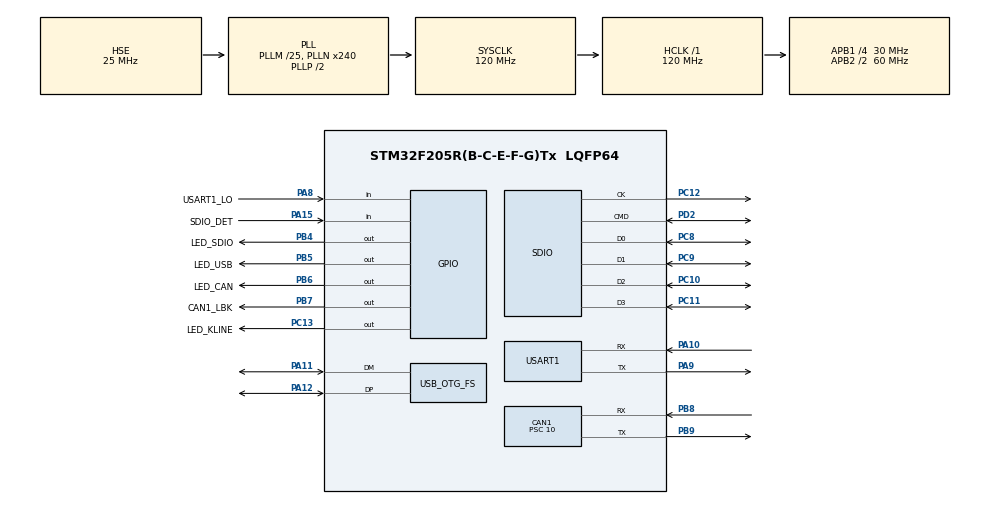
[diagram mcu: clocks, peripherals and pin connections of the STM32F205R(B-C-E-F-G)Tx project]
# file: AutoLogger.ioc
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CAN1.BS1=CAN_BS1_4TQ
CAN1.CalculateBaudRate=499999
CAN1.CalculateTimeBit=2000
CAN1.CalculateTimeQuantum=333.33333333333337
CAN1.Prescaler=10
CAN1.SJW=CAN_SJW_2TQ
Dma.Request0=SDIO_RX
Dma.Request1=SDIO_TX
Dma.Request2=USART1_RX
Dma.Request3=USART1_TX
Dma.SDIO_RX.0.Direction=DMA_PERIPH_TO_MEMORY
Dma.SDIO_RX.0.FIFOMode=DMA_FIFOMODE_ENABLE
Dma.SDIO_RX.0.FIFOThreshold=DMA_FIFO_THRESHOLD_FULL
Dma.SDIO_RX.0.Instance=DMA2_Stream3
Dma.SDIO_RX.0.MemBurst=DMA_MBURST_SINGLE
Dma.SDIO_RX.0.MemDataAlignment=DMA_MDATAALIGN_BYTE
Dma.SDIO_RX.0.MemInc=DMA_MINC_ENABLE
Dma.SDIO_RX.0.Mode=DMA_PFCTRL
Dma.SDIO_RX.0.PeriphBurst=DMA_PBURST_INC4
Dma.SDIO_RX.0.PeriphDataAlignment=DMA_PDATAALIGN_WORD
Dma.SDIO_RX.0.PeriphInc=DMA_PINC_DISABLE
Dma.SDIO_RX.0.Priority=DMA_PRIORITY_LOW
Dma.SDIO_TX.1.Direction=DMA_MEMORY_TO_PERIPH
Dma.SDIO_TX.1.FIFOMode=DMA_FIFOMODE_ENABLE
Dma.SDIO_TX.1.FIFOThreshold=DMA_FIFO_THRESHOLD_FULL
Dma.SDIO_TX.1.Instance=DMA2_Stream6
Dma.SDIO_TX.1.MemBurst=DMA_MBURST_SINGLE
Dma.SDIO_TX.1.MemDataAlignment=DMA_MDATAALIGN_BYTE
Dma.SDIO_TX.1.MemInc=DMA_MINC_ENABLE
Dma.SDIO_TX.1.Mode=DMA_PFCTRL
Dma.SDIO_TX.1.PeriphBurst=DMA_PBURST_INC4
Dma.SDIO_TX.1.PeriphDataAlignment=DMA_PDATAALIGN_WORD
Dma.SDIO_TX.1.PeriphInc=DMA_PINC_DISABLE
Dma.SDIO_TX.1.Priority=DMA_PRIORITY_LOW
Dma.USART1_RX.2.Direction=DMA_PERIPH_TO_MEMORY
Dma.USART1_RX.2.FIFOMode=DMA_FIFOMODE_DISABLE
Dma.USART1_RX.2.Instance=DMA2_Stream2
Dma.USART1_RX.2.MemDataAlignment=DMA_MDATAALIGN_BYTE
Dma.USART1_RX.2.MemInc=DMA_MINC_ENABLE
Dma.USART1_RX.2.Mode=DMA_CIRCULAR
Dma.USART1_RX.2.PeriphDataAlignment=DMA_PDATAALIGN_BYTE
Dma.USART1_RX.2.PeriphInc=DMA_PINC_DISABLE
Dma.USART1_RX.2.Priority=DMA_PRIORITY_LOW
Dma.USART1_TX.3.Direction=DMA_MEMORY_TO_PERIPH
Dma.USART1_TX.3.FIFOMode=DMA_FIFOMODE_DISABLE
Dma.USART1_TX.3.Instance=DMA2_Stream7
Dma.USART1_TX.3.MemDataAlignment=DMA_MDATAALIGN_BYTE
Dma.USART1_TX.3.MemInc=DMA_MINC_ENABLE
Dma.USART1_TX.3.Mode=DMA_NORMAL
Dma.USART1_TX.3.PeriphDataAlignment=DMA_PDATAALIGN_BYTE
Dma.USART1_TX.3.PeriphInc=DMA_PINC_DISABLE
Dma.USART1_TX.3.Priority=DMA_PRIORITY_LOW
FATFS.BSP.number=1
FATFS._USE_FIND=1
FATFS0.BSP.STBoard=false
FATFS0.BSP.api=Unknown
FATFS0.BSP.i2caddr=0
FATFS0.BSP.instance=PA15
FATFS0.BSP.ip=GPIO
FATFS0.BSP.mode=Input
FATFS0.BSP.name=Detect_SDIO
FATFS0.BSP.solution=PA15
FREERTOS.Tasks01=defaultTask,24,256,StartDefaultTask,Default,NULL,Dynamic,NULL,NULL
FREERTOS.configMINIMAL_STACK_SIZE=256
FREERTOS.configUSE_NEWLIB_REENTRANT=1
Mcu.Family=STM32F2
Mcu.Name=STM32F205R(B-C-E-F-G)Tx
Mcu.Package=LQFP64
NVIC.CAN1_RX0_IRQn=true\:5\:0\:false\:false\:true\:true\:true\:true\:true
NVIC.CAN1_RX1_IRQn=true\:5\:0\:false\:false\:true\:true\:true\:true\:true
NVIC.CAN1_SCE_IRQn=true\:5\:0\:false\:false\:true\:true\:true\:true\:true
NVIC.CAN1_TX_IRQn=true\:5\:0\:false\:false\:true\:true\:true\:true\:true
NVIC.DMA2_Stream2_IRQn=true\:5\:0\:false\:false\:true\:true\:false\:true\:true
NVIC.DMA2_Stream3_IRQn=true\:5\:0\:false\:false\:true\:true\:false\:true\:true
NVIC.DMA2_Stream6_IRQn=true\:5\:0\:false\:false\:true\:true\:false\:true\:true
NVIC.DMA2_Stream7_IRQn=true\:5\:0\:false\:false\:true\:true\:false\:true\:true
NVIC.OTG_FS_IRQn=true\:5\:0\:false\:false\:true\:true\:true\:true\:true
NVIC.PriorityGroup=NVIC_PRIORITYGROUP_4
NVIC.SDIO_IRQn=true\:5\:0\:false\:false\:true\:true\:true\:true\:true
NVIC.TIM7_IRQn=true\:5\:0\:false\:false\:true\:true\:true\:true\:true
NVIC.USART1_IRQn=true\:5\:0\:false\:false\:true\:true\:true\:true\:true
PA10.GPIO_PuPd=GPIO_PULLUP
PA10.Mode=Asynchronous
PA10.Signal=USART1_RX
PA11.GPIO_PuPd=GPIO_PULLUP
PA11.Mode=Host_Only
PA11.Signal=USB_OTG_FS_DM
PA12.GPIO_PuPd=GPIO_PULLUP
PA12.Mode=Host_Only
PA12.Signal=USB_OTG_FS_DP
PA13.Mode=Trace_Asynchronous_SW
PA13.Signal=SYS_JTMS-SWDIO
PA14.Mode=Trace_Asynchronous_SW
PA14.Signal=SYS_JTCK-SWCLK
PA15.GPIO_Label=SDIO_DET
PA15.GPIO_PuPd=GPIO_PULLUP
PA15.Signal=GPIO_Input
PA8.GPIO_Label=USART1_LO
PA8.GPIO_PuPd=GPIO_PULLUP
PA8.Signal=GPIO_Input
PA9.GPIO_PuPd=GPIO_PULLUP
PA9.Mode=Asynchronous
PA9.Signal=USART1_TX
PB3.Mode=Trace_Asynchronous_SW
PB3.Signal=SYS_JTDO-SWO
PB4.GPIO_Label=LED_SDIO
PB4.GPIO_ModeDefaultOutputPP=GPIO_MODE_OUTPUT_OD
PB4.GPIO_PuPd=GPIO_NOPULL
PB4.PinState=GPIO_PIN_SET
PB4.Signal=GPIO_Output
PB5.GPIO_Label=LED_USB
PB5.GPIO_ModeDefaultOutputPP=GPIO_MODE_OUTPUT_OD
PB5.GPIO_PuPd=GPIO_NOPULL
PB5.PinState=GPIO_PIN_SET
PB5.Signal=GPIO_Output
PB6.GPIO_Label=LED_CAN
PB6.GPIO_ModeDefaultOutputPP=GPIO_MODE_OUTPUT_OD
PB6.GPIO_PuPd=GPIO_NOPULL
PB6.PinState=GPIO_PIN_SET
PB6.Signal=GPIO_Output
PB7.GPIO_Label=CAN1_LBK
PB7.GPIO_Speed=GPIO_SPEED_FREQ_VERY_HIGH
PB7.PinState=GPIO_PIN_SET
PB7.Signal=GPIO_Output
PB8.GPIO_PuPd=GPIO_PULLUP
PB8.Mode=CAN_Activate
PB8.Signal=CAN1_RX
PB9.GPIO_PuPd=GPIO_PULLUP
PB9.Mode=CAN_Activate
PB9.Signal=CAN1_TX
PC10.GPIO_PuPd=GPIO_PULLUP
PC10.Mode=SD_4_bits_Wide_bus
PC10.Signal=SDIO_D2
PC11.GPIO_PuPd=GPIO_PULLUP
PC11.Mode=SD_4_bits_Wide_bus
PC11.Signal=SDIO_D3
PC12.GPIO_PuPd=GPIO_PULLUP
PC12.Mode=SD_4_bits_Wide_bus
PC12.Signal=SDIO_CK
PC13.GPIO_Label=LED_KLINE
PC13.GPIO_ModeDefaultOutputPP=GPIO_MODE_OUTPUT_OD
PC13.GPIO_PuPd=GPIO_NOPULL
PC13.PinState=GPIO_PIN_SET
PC13.Signal=GPIO_Output
PC8.GPIO_PuPd=GPIO_PULLUP
PC8.Mode=SD_4_bits_Wide_bus
PC8.Signal=SDIO_D0
PC9.GPIO_PuPd=GPIO_PULLUP
PC9.Mode=SD_4_bits_Wide_bus
PC9.Signal=SDIO_D1
PD2.GPIO_PuPd=GPIO_PULLUP
PD2.Mode=SD_4_bits_Wide_bus
PD2.Signal=SDIO_CMD
PH0-OSC_IN.Mode=HSE-External-Oscillator
PH0-OSC_IN.Signal=RCC_OSC_IN
PH1-OSC_OUT.Mode=HSE-External-Oscillator
PH1-OSC_OUT.Signal=RCC_OSC_OUT
ProjectManager.HeapSize=0x200
ProjectManager.StackSize=0x400
ProjectManager.TargetToolchain=STM32CubeIDE
RCC.48MHZClocksFreq_Value=48000000
RCC.AHBFreq_Value=120000000
RCC.APB1CLKDivider=RCC_HCLK_DIV4
RCC.APB1Freq_Value=30000000
RCC.APB1TimFreq_Value=60000000
RCC.APB2CLKDivider=RCC_HCLK_DIV2
RCC.APB2Freq_Value=60000000
RCC.APB2TimFreq_Value=120000000
RCC.CortexFreq_Value=120000000
RCC.HCLKFreq_Value=120000000
RCC.HSE_VALUE=25000000
RCC.HSI_VALUE=16000000
RCC.LSE_VALUE=32768
RCC.PLLM=25
RCC.PLLN=240
RCC.PLLQ=5
RCC.PLLSourceVirtual=RCC_PLLSOURCE_HSE
RCC.RCC_RTC_Clock_SourceVirtual=RCC_RTCCLKSOURCE_HSE_DIV25
RCC.RCC_RTC_Clock_Source_FROM_HSE=RCC_RTCCLKSOURCE_HSE_DIV25
RCC.SYSCLKFreq_VALUE=120000000
RCC.SYSCLKSource=RCC_SYSCLKSOURCE_PLLCLK
RCC.VCOOutputFreq_Value=240000000
RTC.AsynchPrediv=49
RTC.SynchPrediv=19999
TIM7.Period=1000-1
TIM7.Prescaler=60-1
USART1.VirtualMode=VM_ASYNC
USB_HOST.USBH_HandleTypeDef-MSC_FS=hUsbHostFS
USB_HOST.VirtualModeFS=Msc
USB_OTG_FS.VirtualMode=Host_Only
USB_OTG_FS.phy_itface=HCD_PHY_EMBEDDED
VP_FATFS_VS_SDIO.Mode=SDIO
VP_FATFS_VS_USB.Mode=USB
VP_FREERTOS_VS_CMSIS_V2.Mode=CMSIS_V2
VP_IWDG_VS_IWDG.Mode=IWDG_Activate
VP_RTC_VS_RTC_Activate.Mode=RTC_Enabled
VP_TIM7_VS_ClockSourceINT.Mode=Enable_Timer
VP_USB_HOST_VS_USB_HOST_MSC_FS.Mode=MSC_FS
board=custom

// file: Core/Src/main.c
#include "main.h"
#include "cmsis_os.h"
#include "fatfs.h"
#include "led.h"
#include "can.h"

CAN_HandleTypeDef hcan1;

IWDG_HandleTypeDef hiwdg;

RTC_HandleTypeDef hrtc;
RTC_TimeTypeDef sTime;
RTC_DateTypeDef sDate;

SD_HandleTypeDef hsd;
DMA_HandleTypeDef hdma_sdio_rx;
DMA_HandleTypeDef hdma_sdio_tx;

TIM_HandleTypeDef htim7;

UART_HandleTypeDef huart1;
DMA_HandleTypeDef hdma_usart1_rx;
DMA_HandleTypeDef hdma_usart1_tx;

void SystemClock_Config(void);
static void MX_GPIO_Init(void);
static void MX_DMA_Init(void);
static void MX_SDIO_SD_Init(void);
static void MX_USART1_UART_Init(void);
static void MX_CAN1_Init(void);
static void MX_IWDG_Init(void);
static void MX_RTC_Init(void);
static void MX_TIM7_Init(void);
extern void tasksInit(void);

void HAL_CAN_TxMailbox0AbortCallback(CAN_HandleTypeDef *hcan)
{
  if(hcan == &hcan1) {
    can_txfifo_aborted_callback(hcan, CAN_TX_MAILBOX0);
  }
}

void HAL_CAN_TxMailbox1AbortCallback(CAN_HandleTypeDef *hcan)
{
  if(hcan == &hcan1) {
    can_txfifo_aborted_callback(hcan, CAN_TX_MAILBOX1);
  }
}

void HAL_CAN_TxMailbox2AbortCallback(CAN_HandleTypeDef *hcan)
{
  if(hcan == &hcan1) {
    can_txfifo_aborted_callback(hcan, CAN_TX_MAILBOX2);
  }
}

void HAL_CAN_TxMailbox0CompleteCallback(CAN_HandleTypeDef *hcan)
{
  if(hcan == &hcan1) {
    can_txfifo_completed_callback(hcan, CAN_TX_MAILBOX0);
  }
}

void HAL_CAN_TxMailbox1CompleteCallback(CAN_HandleTypeDef *hcan)
{
  if(hcan == &hcan1) {
    can_txfifo_completed_callback(hcan, CAN_TX_MAILBOX1);
  }
}

void HAL_CAN_TxMailbox2CompleteCallback(CAN_HandleTypeDef *hcan)
{
  if(hcan == &hcan1) {
    can_txfifo_completed_callback(hcan, CAN_TX_MAILBOX2);
  }
}

void HAL_CAN_RxFifo0MsgPendingCallback(CAN_HandleTypeDef *hcan)
{
  if(hcan == &hcan1) {
    can_rxfifo_pending_callback(hcan, CAN_RX_FIFO0);
  }
}

void HAL_CAN_RxFifo1MsgPendingCallback(CAN_HandleTypeDef *hcan)
{
  if(hcan == &hcan1) {
    can_rxfifo_pending_callback(hcan, CAN_RX_FIFO1);
  }
}

int main(void)
{
  HAL_Init();

  SystemClock_Config();

  MX_GPIO_Init();
  MX_DMA_Init();
  //MX_IWDG_Init();
  MX_SDIO_SD_Init();
  MX_USART1_UART_Init();
  MX_FATFS_Init();
  MX_CAN1_Init();
  MX_RTC_Init();
  MX_TIM7_Init();

  osKernelInitialize();

  tasksInit();

  led_init();
  led_register(LedUsb, LED_USB_GPIO_Port, LED_USB_Pin, LedOff);
  led_register(LedSdio, LED_SDIO_GPIO_Port, LED_SDIO_Pin, LedOff);
  led_register(LedCan, LED_CAN_GPIO_Port, LED_CAN_Pin, LedOff);
  led_register(LedKline, LED_KLINE_GPIO_Port, LED_KLINE_Pin, LedOff);

  HAL_TIM_Base_Start_IT(&htim7);

  osKernelStart();

  while (1)
  {
  }
}

void SystemClock_Config(void)
{
  RCC_OscInitTypeDef RCC_OscInitStruct = {0};
  RCC_ClkInitTypeDef RCC_ClkInitStruct = {0};
  RCC_PeriphCLKInitTypeDef PeriphClkInitStruct = {0};

  /** Initializes the RCC Oscillators according to the specified parameters
  * in the RCC_OscInitTypeDef structure.
  */
  RCC_OscInitStruct.OscillatorType = RCC_OSCILLATORTYPE_LSI|RCC_OSCILLATORTYPE_HSE;
  RCC_OscInitStruct.HSEState = RCC_HSE_ON;
  RCC_OscInitStruct.LSIState = RCC_LSI_ON;
  RCC_OscInitStruct.PLL.PLLState = RCC_PLL_ON;
  RCC_OscInitStruct.PLL.PLLSource = RCC_PLLSOURCE_HSE;
  RCC_OscInitStruct.PLL.PLLM = 25;
  RCC_OscInitStruct.PLL.PLLN = 240;
  RCC_OscInitStruct.PLL.PLLP = RCC_PLLP_DIV2;
  RCC_OscInitStruct.PLL.PLLQ = 5;
  if (HAL_RCC_OscConfig(&RCC_OscInitStruct) != HAL_OK)
  {
    Error_Handler();
  }

  /** Initializes the CPU, AHB and APB buses clocks
  */
  RCC_ClkInitStruct.ClockType = RCC_CLOCKTYPE_HCLK|RCC_CLOCKTYPE_SYSCLK
                              |RCC_CLOCKTYPE_PCLK1|RCC_CLOCKTYPE_PCLK2;
  RCC_ClkInitStruct.SYSCLKSource = RCC_SYSCLKSOURCE_PLLCLK;
  RCC_ClkInitStruct.AHBCLKDivider = RCC_SYSCLK_DIV1;
  RCC_ClkInitStruct.APB1CLKDivider = RCC_HCLK_DIV4;
  RCC_ClkInitStruct.APB2CLKDivider = RCC_HCLK_DIV2;

  if (HAL_RCC_ClockConfig(&RCC_ClkInitStruct, FLASH_LATENCY_3) != HAL_OK)
  {
    Error_Handler();
  }
  PeriphClkInitStruct.PeriphClockSelection = RCC_PERIPHCLK_RTC;
  PeriphClkInitStruct.RTCClockSelection = RCC_RTCCLKSOURCE_HSE_DIV25;
  if (HAL_RCCEx_PeriphCLKConfig(&PeriphClkInitStruct) != HAL_OK)
  {
    Error_Handler();
  }
}

static void MX_CAN1_Init(void)
{

  hcan1.Instance = CAN1;
  hcan1.Init.Prescaler = 10;
  hcan1.Init.Mode = CAN_MODE_NORMAL;
  hcan1.Init.SyncJumpWidth = CAN_SJW_2TQ;
  hcan1.Init.TimeSeg1 = CAN_BS1_3TQ;
  hcan1.Init.TimeSeg2 = CAN_BS2_2TQ;
  hcan1.Init.TimeTriggeredMode = DISABLE;
  hcan1.Init.AutoBusOff = DISABLE;
  hcan1.Init.AutoWakeUp = DISABLE;
  hcan1.Init.AutoRetransmission = ENABLE;
  hcan1.Init.ReceiveFifoLocked = DISABLE;
  hcan1.Init.TransmitFifoPriority = DISABLE;
  if (HAL_CAN_Init(&hcan1) != HAL_OK)
  {
    Error_Handler();
  }

}

static void MX_IWDG_Init(void)
{

  hiwdg.Instance = IWDG;
  hiwdg.Init.Prescaler = IWDG_PRESCALER_4;
  hiwdg.Init.Reload = 4095;
  if (HAL_IWDG_Init(&hiwdg) != HAL_OK)
  {
    Error_Handler();
  }

}

static void MX_RTC_Init(void)
{

  /** Initialize RTC Only
  */
  hrtc.Instance = RTC;
  hrtc.Init.HourFormat = RTC_HOURFORMAT_24;
  hrtc.Init.AsynchPrediv = 49;
  hrtc.Init.SynchPrediv = 19999;
  hrtc.Init.OutPut = RTC_OUTPUT_DISABLE;
  hrtc.Init.OutPutPolarity = RTC_OUTPUT_POLARITY_HIGH;
  hrtc.Init.OutPutType = RTC_OUTPUT_TYPE_OPENDRAIN;
  if (HAL_RTC_Init(&hrtc) != HAL_OK)
  {
    Error_Handler();
  }
  /* USER CODE BEGIN RTC_Init 2 */

  sDate.Date = 1;
  sDate.Month = 1;
  sDate.Year = 24;

  sTime.Hours = 9;
  sTime.Minutes = 0;
  sTime.Seconds = 0;

  if (HAL_RTC_SetTime(&hrtc, &sTime, FORMAT_BIN) != HAL_OK)
  {
    Error_Handler();
  }
  if (HAL_RTC_SetDate(&hrtc, &sDate, FORMAT_BIN) != HAL_OK)
  {
    Error_Handler();
  }

  /* USER CODE END RTC_Init 2 */

}

static void MX_SDIO_SD_Init(void)
{

  hsd.Instance = SDIO;
  hsd.Init.ClockEdge = SDIO_CLOCK_EDGE_RISING;
  hsd.Init.ClockBypass = SDIO_CLOCK_BYPASS_DISABLE;
  hsd.Init.ClockPowerSave = SDIO_CLOCK_POWER_SAVE_DISABLE;
  hsd.Init.BusWide = SDIO_BUS_WIDE_1B;
  hsd.Init.HardwareFlowControl = SDIO_HARDWARE_FLOW_CONTROL_DISABLE;
  hsd.Init.ClockDiv = 0;

}

static void MX_TIM7_Init(void)
{

  TIM_MasterConfigTypeDef sMasterConfig = {0};

  htim7.Instance = TIM7;
  htim7.Init.Prescaler = 60-1;
  htim7.Init.CounterMode = TIM_COUNTERMODE_UP;
  htim7.Init.Period = 1000-1;
  htim7.Init.AutoReloadPreload = TIM_AUTORELOAD_PRELOAD_DISABLE;
  if (HAL_TIM_Base_Init(&htim7) != HAL_OK)
  {
    Error_Handler();
  }
  sMasterConfig.MasterOutputTrigger = TIM_TRGO_RESET;
  sMasterConfig.MasterSlaveMode = TIM_MASTERSLAVEMODE_DISABLE;
  if (HAL_TIMEx_MasterConfigSynchronization(&htim7, &sMasterConfig) != HAL_OK)
  {
    Error_Handler();
  }

}

static void MX_USART1_UART_Init(void)
{

  huart1.Instance = USART1;
  huart1.Init.BaudRate = 10400;
  huart1.Init.WordLength = UART_WORDLENGTH_8B;
  huart1.Init.StopBits = UART_STOPBITS_1;
  huart1.Init.Parity = UART_PARITY_NONE;
  huart1.Init.Mode = UART_MODE_TX_RX;
  huart1.Init.HwFlowCtl = UART_HWCONTROL_NONE;
  huart1.Init.OverSampling = UART_OVERSAMPLING_16;
  if (HAL_UART_Init(&huart1) != HAL_OK)
  {
    Error_Handler();
  }

}

static void MX_DMA_Init(void)
{

  /* DMA controller clock enable */
  __HAL_RCC_DMA2_CLK_ENABLE();

  /* DMA interrupt init */
  /* DMA2_Stream2_IRQn interrupt configuration */
  HAL_NVIC_SetPriority(DMA2_Stream2_IRQn, 12, 0);
  HAL_NVIC_EnableIRQ(DMA2_Stream2_IRQn);
  /* DMA2_Stream3_IRQn interrupt configuration */
  HAL_NVIC_SetPriority(DMA2_Stream3_IRQn, 11, 0);
  HAL_NVIC_EnableIRQ(DMA2_Stream3_IRQn);
  /* DMA2_Stream6_IRQn interrupt configuration */
  HAL_NVIC_SetPriority(DMA2_Stream6_IRQn, 11, 0);
  HAL_NVIC_EnableIRQ(DMA2_Stream6_IRQn);
  /* DMA2_Stream7_IRQn interrupt configuration */
  HAL_NVIC_SetPriority(DMA2_Stream7_IRQn, 12, 0);
  HAL_NVIC_EnableIRQ(DMA2_Stream7_IRQn);

}

static void MX_GPIO_Init(void)
{
  GPIO_InitTypeDef GPIO_InitStruct = {0};

  /* GPIO Ports Clock Enable */
  __HAL_RCC_GPIOC_CLK_ENABLE();
  __HAL_RCC_GPIOH_CLK_ENABLE();
  __HAL_RCC_GPIOA_CLK_ENABLE();
  __HAL_RCC_GPIOD_CLK_ENABLE();
  __HAL_RCC_GPIOB_CLK_ENABLE();

  /*Configure GPIO pin Output Level */
  HAL_GPIO_WritePin(LED_KLINE_GPIO_Port, LED_KLINE_Pin, GPIO_PIN_SET);

  /*Configure GPIO pin Output Level */
  HAL_GPIO_WritePin(GPIOB, LED_SDIO_Pin|LED_USB_Pin|LED_CAN_Pin|CAN1_LBK_Pin, GPIO_PIN_SET);

  /*Configure GPIO pin : LED_KLINE_Pin */
  GPIO_InitStruct.Pin = LED_KLINE_Pin;
  GPIO_InitStruct.Mode = GPIO_MODE_OUTPUT_OD;
  GPIO_InitStruct.Pull = GPIO_NOPULL;
  GPIO_InitStruct.Speed = GPIO_SPEED_FREQ_LOW;
  HAL_GPIO_Init(LED_KLINE_GPIO_Port, &GPIO_InitStruct);

  /*Configure GPIO pins : USART1_LO_Pin SDIO_DET_Pin */
  GPIO_InitStruct.Pin = USART1_LO_Pin|SDIO_DET_Pin;
  GPIO_InitStruct.Mode = GPIO_MODE_INPUT;
  GPIO_InitStruct.Pull = GPIO_PULLUP;
  HAL_GPIO_Init(GPIOA, &GPIO_InitStruct);

  /*Configure GPIO pins : LED_SDIO_Pin LED_USB_Pin LED_CAN_Pin */
  GPIO_InitStruct.Pin = LED_SDIO_Pin|LED_USB_Pin|LED_CAN_Pin;
  GPIO_InitStruct.Mode = GPIO_MODE_OUTPUT_OD;
  GPIO_InitStruct.Pull = GPIO_NOPULL;
  GPIO_InitStruct.Speed = GPIO_SPEED_FREQ_LOW;
  HAL_GPIO_Init(GPIOB, &GPIO_InitStruct);

  /*Configure GPIO pin : CAN1_LBK_Pin */
  GPIO_InitStruct.Pin = CAN1_LBK_Pin;
  GPIO_InitStruct.Mode = GPIO_MODE_ANALOG;
  GPIO_InitStruct.Pull = GPIO_NOPULL;
  GPIO_InitStruct.Speed = GPIO_SPEED_FREQ_VERY_HIGH;
  HAL_GPIO_Init(CAN1_LBK_GPIO_Port, &GPIO_InitStruct);

}

void Error_Handler(void)
{
  __disable_irq();
  while (1)
  {
  }
}

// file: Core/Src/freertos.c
/* USER CODE BEGIN Header */
/**
  ******************************************************************************
  * File Name          : freertos.c
  * Description        : Code for freertos applications
  ******************************************************************************
  * @attention
  *
  * Copyright (c) 2022 STMicroelectronics.
  * All rights reserved.
  *
  * This software is licensed under terms that can be found in the LICENSE file
  * in the root directory of this software component.
  * If no LICENSE file comes with this software, it is provided AS-IS.
  *
  ******************************************************************************
  */
/* USER CODE END Header */

#include "cmsis_os.h"
#include "main.h"
#include "usb_host.h"
#include "fatfs.h"
#include "xProFIFO.h"
#include "led.h"
#include "structs.h"
#include "can.h"
#include "can_signals.h"
#include "can_signals_db.h"
#include <stdio.h>
#include <string.h>

#define CAN_LOOPBACK() HAL_GPIO_WritePin(CAN1_LBK_GPIO_Port, CAN1_LBK_Pin, GPIO_PIN_SET)
#define CAN_NORMAL() HAL_GPIO_WritePin(CAN1_LBK_GPIO_Port, CAN1_LBK_Pin, GPIO_PIN_RESET)

extern CAN_HandleTypeDef hcan1;
extern UART_HandleTypeDef huart1;
extern IWDG_HandleTypeDef hiwdg;

extern RTC_HandleTypeDef hrtc;
extern RTC_TimeTypeDef sTime;
extern RTC_DateTypeDef sDate;

/* Definitions for defaultTask */
osThreadId_t h_task_time;
osThreadId_t h_task_usb;
osThreadId_t h_task_sdio;
osThreadId_t h_task_can;
osThreadId_t h_task_kline;

volatile uint64_t gTick64 = 0;

char *uint64_to_str(uint64_t n, char dest[static 21]) {
    dest += 20;
    *dest-- = 0;
    while (n) {
        *dest-- = (n % 10) + '0';
        n /= 10;
    }
    return dest + 1;
}

#define LOG10_FROM_2_TO_64_PLUS_1  21
#define UINT64_TO_STR(n)  uint64_to_str(n, (char[21]){0})

typedef struct {
    const char *name;
    uint8_t type;
    uint32_t offset;
}sParameter;

/*
 * 0 = uint64_t
 * 1 = char *
 * 2 = int32_t
 * 3 = float
 * 4 = uint8_t
 * 5 = uint16_t
 */

const sParameter gParameters[] = {
    {"AdcKnockVoltage",           3, OFFSETOF(sParameters, AdcKnockVoltage)},
    {"AdcAirTemp",                3, OFFSETOF(sParameters, AdcAirTemp)},
    {"AdcEngineTemp",             3, OFFSETOF(sParameters, AdcEngineTemp)},
    {"AdcManifoldAirPressure",    3, OFFSETOF(sParameters, AdcManifoldAirPressure)},
    {"AdcThrottlePosition",       3, OFFSETOF(sParameters, AdcThrottlePosition)},
    {"AdcReferenceVoltage",       3, OFFSETOF(sParameters, AdcReferenceVoltage)},
    {"AdcLambdaUR",               3, OFFSETOF(sParameters, AdcLambdaUR)},
    {"AdcLambdaUA",               3, OFFSETOF(sParameters, AdcLambdaUA)},
    {"AdcEtcTps1",                3, OFFSETOF(sParameters, AdcEtcTps1)},
    {"AdcEtcTps2",                3, OFFSETOF(sParameters, AdcEtcTps2)},
    {"AdcEtcPedal1",              3, OFFSETOF(sParameters, AdcEtcPedal1)},
    {"AdcEtcPedal2",              3, OFFSETOF(sParameters, AdcEtcPedal2)},
    {"AdcEtcRsvd5",               3, OFFSETOF(sParameters, AdcEtcRsvd5)},
    {"AdcEtcRsvd6",               3, OFFSETOF(sParameters, AdcEtcRsvd6)},
    {"AdcEtcReferenceVoltage",    3, OFFSETOF(sParameters, AdcEtcReferenceVoltage)},
    {"AdcEtcPowerVoltage",        3, OFFSETOF(sParameters, AdcEtcPowerVoltage)},
    {"ThrottlePosition",          3, OFFSETOF(sParameters, ThrottlePosition)},
    {"PedalPosition",             3, OFFSETOF(sParameters, PedalPosition)},
    {"ThrottleDefaultPosition",   3, OFFSETOF(sParameters, ThrottleDefaultPosition)},
    {"ThrottleTargetPosition",    3, OFFSETOF(sParameters, ThrottleTargetPosition)},
    {"WishThrottleTargetPosition",3, OFFSETOF(sParameters, WishThrottleTargetPosition)},
    {"KnockSensor",               3, OFFSETOF(sParameters, KnockSensor)},
    {"KnockSensorFiltered",       3, OFFSETOF(sParameters, KnockSensorFiltered)},
    {"KnockSensorDetonate",       3, OFFSETOF(sParameters, KnockSensorDetonate)},
    {"KnockZone",                 3, OFFSETOF(sParameters, KnockZone)},
    {"KnockAdvance",              3, OFFSETOF(sParameters, KnockAdvance)},
    {"KnockSaturation",           3, OFFSETOF(sParameters, KnockSaturation)},
    {"AirTemp",                   3, OFFSETOF(sParameters, AirTemp)},
    {"EngineTemp",                3, OFFSETOF(sParameters, EngineTemp)},
    {"CalculatedAirTemp",         3, OFFSETOF(sParameters, CalculatedAirTemp)},
    {"ManifoldAirPressure",       3, OFFSETOF(sParameters, ManifoldAirPressure)},
    {"ReferenceVoltage",          3, OFFSETOF(sParameters, ReferenceVoltage)},
    {"PowerVoltage",              3, OFFSETOF(sParameters, PowerVoltage)},
    {"FuelRatio",                 3, OFFSETOF(sParameters, FuelRatio)},
    {"FuelRatioDiff",             3, OFFSETOF(sParameters, FuelRatioDiff)},
    {"LambdaValue",               3, OFFSETOF(sParameters, LambdaValue)},
    {"LambdaTemperature",         3, OFFSETOF(sParameters, LambdaTemperature)},
    {"LambdaHeaterVoltage",       3, OFFSETOF(sParameters, LambdaHeaterVoltage)},
    {"ShortTermCorrection",       3, OFFSETOF(sParameters, ShortTermCorrection)},
    {"LongTermCorrection",        3, OFFSETOF(sParameters, LongTermCorrection)},
    {"IdleCorrection",            3, OFFSETOF(sParameters, IdleCorrection)},
    {"RPM",                       3, OFFSETOF(sParameters, RPM)},
    {"Speed",                     3, OFFSETOF(sParameters, Speed)},
    {"MassAirFlow",               3, OFFSETOF(sParameters, MassAirFlow)},
    {"CyclicAirFlow",             3, OFFSETOF(sParameters, CyclicAirFlow)},
    {"EffectiveVolume",           3, OFFSETOF(sParameters, EffectiveVolume)},
    {"EngineLoad",                3, OFFSETOF(sParameters, EngineLoad)},
    {"EstimatedPower",            3, OFFSETOF(sParameters, EstimatedPower)},
    {"EstimatedTorque",           3, OFFSETOF(sParameters, EstimatedTorque)},
    {"WishFuelRatio",             3, OFFSETOF(sParameters, WishFuelRatio)},
    {"IdleValvePosition",         3, OFFSETOF(sParameters, IdleValvePosition)},
    {"IdleRegThrRPM",             3, OFFSETOF(sParameters, IdleRegThrRPM)},
    {"WishIdleRPM",               3, OFFSETOF(sParameters, WishIdleRPM)},
    {"WishIdleMassAirFlow",       3, OFFSETOF(sParameters, WishIdleMassAirFlow)},
    {"WishIdleValvePosition",     3, OFFSETOF(sParameters, WishIdleValvePosition)},
    {"WishIdleIgnitionAdvance",   3, OFFSETOF(sParameters, WishIdleIgnitionAdvance)},
    {"IgnitionAdvance",           3, OFFSETOF(sParameters, IgnitionAdvance)},
    {"InjectionPhase",            3, OFFSETOF(sParameters, InjectionPhase)},
    {"InjectionPhaseDuration",    3, OFFSETOF(sParameters, InjectionPhaseDuration)},
    {"InjectionPulse",            3, OFFSETOF(sParameters, InjectionPulse)},
    {"InjectionDutyCycle",        3, OFFSETOF(sParameters, InjectionDutyCycle)},
    {"InjectionEnrichment",       3, OFFSETOF(sParameters, InjectionEnrichment)},
    {"InjectionLag",              3, OFFSETOF(sParameters, InjectionLag)},
    {"IgnitionPulse",             3, OFFSETOF(sParameters, IgnitionPulse)},
    {"IdleSpeedShift",            3, OFFSETOF(sParameters, IdleSpeedShift)},
    {"EnrichmentSyncAmount",      3, OFFSETOF(sParameters, EnrichmentSyncAmount)},
    {"EnrichmentAsyncAmount",     3, OFFSETOF(sParameters, EnrichmentAsyncAmount)},
    {"EnrichmentStartLoad",       3, OFFSETOF(sParameters, EnrichmentStartLoad)},
    {"EnrichmentLoadDerivative",  3, OFFSETOF(sParameters, EnrichmentLoadDerivative)},
    {"DrivenKilometers",          3, OFFSETOF(sParameters, DrivenKilometers)},
    {"FuelConsumed",              3, OFFSETOF(sParameters, FuelConsumed)},
    {"FuelConsumption",           3, OFFSETOF(sParameters, FuelConsumption)},
    {"FuelHourly",                3, OFFSETOF(sParameters, FuelHourly)},
    {"TspsRelativePosition",      3, OFFSETOF(sParameters, TspsRelativePosition)},
    {"IdleWishToRpmRelation",     3, OFFSETOF(sParameters, IdleWishToRpmRelation)},
    {"KnockCount",                5, OFFSETOF(sParameters, KnockCount)},
    {"KnockCountCy1",             5, OFFSETOF(sParameters, KnockCountCy[0])},
    {"KnockCountCy2",             5, OFFSETOF(sParameters, KnockCountCy[1])},
    {"KnockCountCy3",             5, OFFSETOF(sParameters, KnockCountCy[2])},
    {"KnockCountCy4",             5, OFFSETOF(sParameters, KnockCountCy[3])},
    {"SwitchPosition",            4, OFFSETOF(sParameters, SwitchPosition)},
    {"CurrentTable",              4, OFFSETOF(sParameters, CurrentTable)},
    {"InjectorChannel",           4, OFFSETOF(sParameters, InjectorChannel)},
    {"IdleFlag",                  4, OFFSETOF(sParameters, IdleFlag)},
    {"IdleCorrFlag",              4, OFFSETOF(sParameters, IdleCorrFlag)},
    {"IdleEconFlag",              4, OFFSETOF(sParameters, IdleEconFlag)},
    {"LambdaValid",               4, OFFSETOF(sParameters, LambdaValid)},
    {"OilSensor",                 4, OFFSETOF(sParameters, OilSensor)},
    {"FanForceSwitch",            4, OFFSETOF(sParameters, FanForceSwitch)},
    {"HandbrakeSensor",           4, OFFSETOF(sParameters, HandbrakeSensor)},
    {"ChargeSensor",              4, OFFSETOF(sParameters, ChargeSensor)},
    {"ClutchSensor",              4, OFFSETOF(sParameters, ClutchSensor)},
    {"IgnSensor",                 4, OFFSETOF(sParameters, IgnSensor)},
    {"FuelPumpRelay",             4, OFFSETOF(sParameters, FuelPumpRelay)},
    {"FanRelay",                  4, OFFSETOF(sParameters, FanRelay)},
    {"CheckEngine",               4, OFFSETOF(sParameters, CheckEngine)},
    {"StarterRelay",              4, OFFSETOF(sParameters, StarterRelay)},
    {"FanSwitch",                 4, OFFSETOF(sParameters, FanSwitch)},
    {"IgnOutput",                 4, OFFSETOF(sParameters, IgnOutput)},
    {"StartAllowed",              4, OFFSETOF(sParameters, StartAllowed)},
    {"IsRunning",                 4, OFFSETOF(sParameters, IsRunning)},
    {"IsCheckEngine",             4, OFFSETOF(sParameters, IsCheckEngine)},

    {"EtcMotorActiveFlag",        4, OFFSETOF(sParameters, EtcMotorActiveFlag)},
    {"EtcStandaloneFlag",         4, OFFSETOF(sParameters, EtcStandaloneFlag)},
    {"EtcMotorFullCloseFlag",     4, OFFSETOF(sParameters, EtcMotorFullCloseFlag)},

    {"EtcOutCruizeG",             4, OFFSETOF(sParameters, EtcOutCruizeG)},
    {"EtcOutCruizeR",             4, OFFSETOF(sParameters, EtcOutCruizeR)},
    {"EtcOutRsvd3",               4, OFFSETOF(sParameters, EtcOutRsvd3)},
    {"EtcOutRsvd4",               4, OFFSETOF(sParameters, EtcOutRsvd4)},
    {"EtcInCruizeStart",          4, OFFSETOF(sParameters, EtcInCruizeStart)},
    {"EtcInCruizeStop",           4, OFFSETOF(sParameters, EtcInCruizeStop)},
    {"EtcInBrake",                4, OFFSETOF(sParameters, EtcInBrake)},
    {"EtcInRsvd4",                4, OFFSETOF(sParameters, EtcInRsvd4)},
    {"EtcInRsvd5",                4, OFFSETOF(sParameters, EtcInRsvd5)},
    {"EtcInRsvd6",                4, OFFSETOF(sParameters, EtcInRsvd6)},

    {"CylinderIgnitionBitmask",   4, OFFSETOF(sParameters, CylinderIgnitionBitmask)},
    {"CylinderInjectionBitmask",  4, OFFSETOF(sParameters, CylinderInjectionBitmask)}

};

#define BIT_GET(array,bit) ((array)[(bit) >> 3] & (1 << ((bit) & 7)))
#define BIT_SET(array,bit)   ((array)[(bit) >> 3] |= (1 << ((bit) & 7)))
#define BIT_RESET(array,bit)   ((array)[(bit) >> 3] &= ~(1 << ((bit) & 7)))
static uint8_t gConfigBitmap[16] = {0};

const char *gFileInitialHeader = "TimePoint";

typedef struct {
    uint64_t timestamp;
    sParameters params;
}sLoggerParameters;

#define PARAMS_BUFFER_SIZE 40
static sLoggerParameters gParamsBuffer[2][PARAMS_BUFFER_SIZE];
static sProFIFO gParamsFifo[2];

const osThreadAttr_t attrs_task_time = {
  .name = "taskTime",
  .stack_size = 256 * 4,
  .priority = (osPriority_t) osPriorityHigh,
};

const osThreadAttr_t attrs_task_usb = {
  .name = "taskUsb",
  .stack_size = 2048 * 4,
  .priority = (osPriority_t) osPriorityNormal,
};

const osThreadAttr_t attrs_task_sdio = {
  .name = "taskSdio",
  .stack_size = 2048 * 4,
  .priority = (osPriority_t) osPriorityNormal,
};

const osThreadAttr_t attrs_task_can = {
  .name = "taskCan",
  .stack_size = 2048 * 4,
  .priority = (osPriority_t) osPriorityAboveNormal,
};

const osThreadAttr_t attrs_task_kline = {
  .name = "taskKline",
  .stack_size = 2048 * 4,
  .priority = (osPriority_t) osPriorityAboveNormal,
};

void StartTimeTask(void *argument)
{
  for(;;)
  {
    HAL_RTC_GetTime(&hrtc, &sTime, FORMAT_BIN);
    HAL_RTC_GetDate(&hrtc, &sDate, FORMAT_BIN);
    osDelay(100);
  }
}

void HAL_TIM_PeriodElapsedCallback(TIM_HandleTypeDef *htim)
{
  if(htim->Instance == TIM7) {
    led_irq();
    gTick64++;
  }
}

struct sLogDriver {
    uint8_t initialized;
    uint8_t was_initialized;
    FRESULT fres;
    char filename[32];
    char string[128];
    uint16_t filenumber;
    UINT read;
    UINT wrote;
    sLoggerParameters parameters;
    uint64_t InitTime64;
    uint64_t diff;
    uint64_t sync_last;

    eLed led;
    FATFS *fatfs;
    FIL *file;
    const char *path;
    sProFIFO *fifo;
};

static void driver_loop(struct sLogDriver *driver)
{
  uint32_t readpos;

  led_set(driver->led, LedOff);
  led_set_post(driver->led, LedOff);

  for(;;)
  {
    if(!driver->initialized) {
      if(!driver->initialized && driver->was_initialized) {
        f_close(driver->file);
        f_mount(NULL, driver->path, 0);
        driver->was_initialized = 0;
      }

      osDelay(10);

      driver->fres = f_mount(driver->fatfs, driver->path, 1);
      if(driver->fres != FR_OK) {
        led_set(driver->led, LedOff);
        led_set_post(driver->led, LedOff);
        continue;
      }

      led_set(driver->led, LedLong);
      led_set_post(driver->led, LedOn);

      driver->was_initialized = 1;

      sprintf(driver->filename, "%s/params.txt", driver->path);
      driver->fres = f_open(driver->file, driver->filename, FA_OPEN_EXISTING | FA_READ);
      if(driver->fres == FR_OK) {
        if(f_size(driver->file) > 0) {
          memset(gConfigBitmap, 0, sizeof(gConfigBitmap));
          for(readpos = 0; readpos < sizeof(driver->string);) {
            driver->fres = f_read(driver->file, &driver->string[readpos], 1, &driver->read);
            if(driver->fres != FR_OK) { f_close(driver->file); continue; }
            if(driver->string[readpos] == ',' || driver->string[readpos] == '\r' ||
                driver->string[readpos] == '\n' || driver->string[readpos] == ' ' ||
                driver->string[readpos] == '\0') {
              if(readpos > 0) {
                driver->string[readpos] = '\0';
                for(int j = 0; j < ITEMSOF(gParameters); j++) {
                  if(strcmp(gParameters[j].name, driver->string) == 0) {
                    BIT_SET(gConfigBitmap, j);
                    break;
                  }
                }
                readpos = 0;
              }
            } else {
              readpos++;
            }
            if(f_eof(driver->file))
              break;
          }
        }
        f_close(driver->file);
      } else if(driver->fres != FR_NO_FILE) {
        continue;
      }

      sprintf(driver->filename, "%s/log_last.txt", driver->path);
      driver->fres = f_open(driver->file, driver->filename, FA_OPEN_EXISTING | FA_READ);
      if(driver->fres == FR_OK) {
        if(f_size(driver->file) >= sizeof(driver->string)) {
          driver->fres = f_close(driver->file);
          if(driver->fres != FR_OK) { continue; }
          driver->filenumber = 1;
        } else {
          driver->fres = f_read(driver->file, driver->string, f_size(driver->file), &driver->read);
          if(driver->fres != FR_OK) { f_close(driver->file); continue; }
          driver->fres = f_close(driver->file);
          if(driver->fres != FR_OK) { continue; }
          driver->string[driver->read] = 0;
          driver->fres = sscanf(driver->string, "%hu", &driver->filenumber);
          if(driver->fres == 1) {
            driver->filenumber++;
          }

        }
      } else if(driver->fres == FR_NO_FILE) {
        driver->filenumber = 1;
      } else { continue; }

      driver->fres = f_open(driver->file, driver->filename, FA_CREATE_ALWAYS | FA_WRITE);
      if(driver->fres == FR_OK) {
        sprintf(driver->filename, "%05hu", driver->filenumber);
        driver->fres = f_write(driver->file, driver->filename, strlen(driver->filename), &driver->read);
        if(driver->fres != FR_OK) { f_close(driver->file); continue; }
        driver->fres = f_sync(driver->file);
        if(driver->fres != FR_OK) { f_close(driver->file); continue; }
        driver->fres = f_close(driver->file);
        if(driver->fres != FR_OK) { continue; }
      } else {
        osDelay(100);
        continue;
      }

      sprintf(driver->filename, "%s/log_%05hu.eculog", driver->path, driver->filenumber);
      driver->fres = f_open(driver->file, driver->filename, FA_CREATE_ALWAYS | FA_WRITE);
      if(driver->fres != FR_OK) { continue; }
      driver->fres = f_sync(driver->file);
      if(driver->fres != FR_OK) { f_close(driver->file); continue; }

      strcpy(driver->string, gFileInitialHeader);
      driver->fres = f_write(driver->file, driver->string, strlen(driver->string), &driver->wrote);
      if(driver->fres != FR_OK) { f_close(driver->file); continue; }

      for(int i = 0; i < ITEMSOF(gParameters); i++) {
        if(BIT_GET(gConfigBitmap, i)) {
          strcpy(driver->string, ",");
          strcat(driver->string, gParameters[i].name);
          driver->fres = f_write(driver->file, driver->string, strlen(driver->string), &driver->wrote);
          if(driver->fres != FR_OK)
            break;
        }
      }
      if(driver->fres != FR_OK) { f_close(driver->file); continue; }

      strcpy(driver->string, "\r\n");
      driver->fres = f_write(driver->file, driver->string, strlen(driver->string), &driver->wrote);
      if(driver->fres != FR_OK) { f_close(driver->file); continue; }

      driver->fres = f_sync(driver->file);
      if(driver->fres != FR_OK) { f_close(driver->file); continue; }

      driver->initialized = 1;
      driver->InitTime64 = gTick64;
      driver->sync_last = gTick64;

      led_set(driver->led, LedOn);
      led_set_post(driver->led, LedOn);
    }

    if(protPull(driver->fifo, &driver->parameters)) {
      if(driver->parameters.timestamp < driver->InitTime64) {
        driver->InitTime64 = driver->parameters.timestamp;
      }
      driver->diff = driver->parameters.timestamp - driver->InitTime64;
      if(driver->diff > 0) {
        sprintf(driver->string, "%s000", UINT64_TO_STR(driver->diff));
      } else {
        strcpy(driver->string, "0");
      }
      driver->fres = f_write(driver->file, driver->string, strlen(driver->string), &driver->wrote);
      if(driver->fres != FR_OK) { f_close(driver->file); driver->initialized = 0; continue; }
      for(int i = 0; i < ITEMSOF(gParameters);) {
        driver->string[0] = '\0';
        if(BIT_GET(gConfigBitmap, i)) {
          const void *ptr = ((uint8_t *)&driver->parameters.params) + gParameters[i].offset;
          switch(gParameters[i].type) {
            case 1:
              sprintf(driver->string, ",%s", (const char *)ptr);
              break;
            case 2:
              sprintf(driver->string, ",%ld", *(const int32_t *)ptr);
              break;
            case 3:
              sprintf(driver->string, ",%f", *(const float *)ptr);
              break;
            case 4:
              sprintf(driver->string, ",%hu", *(const uint8_t *)ptr);
              break;
            case 5:
              sprintf(driver->string, ",%hu", *(const uint16_t *)ptr);
              break;
            default:
              break;
          }
        }

        if(++i >= ITEMSOF(gParameters)) {
          strcat(driver->string, "\r\n");
        }
        if(driver->string[0]) {
          driver->fres = f_write(driver->file, driver->string, strlen(driver->string), &driver->wrote);
          if(driver->fres != FR_OK) { f_close(driver->file); driver->initialized = 0; continue; }
        }
      }

      if(gTick64 - driver->sync_last > 1000) {
        driver->fres = f_sync(driver->file);
        if(driver->fres != FR_OK) { f_close(driver->file); driver->initialized = 0; continue; }
        driver->sync_last = gTick64;
      }

      led_set(driver->led, LedShortSingle);
    } else {
      osDelay(1);
    }

  }
}

static int8_t ecu_can_process_message(const sCanRawMessage *message, sLoggerParameters *logger_parameters)
{
  const uint32_t messages_count = 12;
  const uint32_t msgs_expected = (1 << messages_count) - 1;
  static uint32_t msgs_bitmap = 0;
  sParameters *parameters = &logger_parameters->params;

  int8_t status = 0;

  sCanMessage * can_msg = can_message_get_msg(message);

  if(can_msg != NULL) {
    switch(can_msg->Id) {
      case 0x020:
        can_signal_get_float(&g_can_message_id020_ECU, &g_can_signal_id020_ECU_AdcKnockVoltage, &parameters->AdcKnockVoltage);
        can_signal_get_float(&g_can_message_id020_ECU, &g_can_signal_id020_ECU_AdcAirTemp, &parameters->AdcAirTemp);
        can_signal_get_float(&g_can_message_id020_ECU, &g_can_signal_id020_ECU_AdcEngineTemp, &parameters->AdcEngineTemp);
        can_signal_get_float(&g_can_message_id020_ECU, &g_can_signal_id020_ECU_AdcManifoldAirPressure, &parameters->AdcManifoldAirPressure);
        can_signal_get_float(&g_can_message_id020_ECU, &g_can_signal_id020_ECU_AdcThrottlePosition, &parameters->AdcThrottlePosition);
        can_signal_get_float(&g_can_message_id020_ECU, &g_can_signal_id020_ECU_AdcReferenceVoltage, &parameters->AdcReferenceVoltage);
        can_signal_get_float(&g_can_message_id020_ECU, &g_can_signal_id020_ECU_AdcLambdaUR, &parameters->AdcLambdaUR);
        can_signal_get_float(&g_can_message_id020_ECU, &g_can_signal_id020_ECU_AdcLambdaUA, &parameters->AdcLambdaUA);
        msgs_bitmap |= 1 << (can_msg->Id - 0x020);
        break;
      case 0x021:
        can_signal_get_float(&g_can_message_id021_ECU, &g_can_signal_id021_ECU_KnockSensor, &parameters->KnockSensor);
        can_signal_get_float(&g_can_message_id021_ECU, &g_can_signal_id021_ECU_KnockSensorFiltered, &parameters->KnockSensorFiltered);
        can_signal_get_float(&g_can_message_id021_ECU, &g_can_signal_id021_ECU_KnockSensorDetonate, &parameters->KnockSensorDetonate);
        can_signal_get_float(&g_can_message_id021_ECU, &g_can_signal_id021_ECU_KnockSaturation, &parameters->KnockSaturation);
        can_signal_get_float(&g_can_message_id021_ECU, &g_can_signal_id021_ECU_KnockAdvance, &parameters->KnockAdvance);
        can_signal_get_uint16(&g_can_message_id021_ECU, &g_can_signal_id021_ECU_KnockCountCy1, &parameters->KnockCountCy[0]);
        can_signal_get_uint16(&g_can_message_id021_ECU, &g_can_signal_id021_ECU_KnockCountCy2, &parameters->KnockCountCy[1]);
        can_signal_get_uint16(&g_can_message_id021_ECU, &g_can_signal_id021_ECU_KnockCountCy3, &parameters->KnockCountCy[2]);
        can_signal_get_uint16(&g_can_message_id021_ECU, &g_can_signal_id021_ECU_KnockCountCy4, &parameters->KnockCountCy[3]);
        can_signal_get_uint16(&g_can_message_id021_ECU, &g_can_signal_id021_ECU_KnockCount, &parameters->KnockCount);
        msgs_bitmap |= 1 << (can_msg->Id - 0x020);
        break;
      case 0x022:
        can_signal_get_float(&g_can_message_id022_ECU, &g_can_signal_id022_ECU_AirTemp, &parameters->AirTemp);
        can_signal_get_float(&g_can_message_id022_ECU, &g_can_signal_id022_ECU_EngineTemp, &parameters->EngineTemp);
        can_signal_get_float(&g_can_message_id022_ECU, &g_can_signal_id022_ECU_CalculatedAirTemp, &parameters->CalculatedAirTemp);
        can_signal_get_float(&g_can_message_id022_ECU, &g_can_signal_id022_ECU_ManifoldAirPressure, &parameters->ManifoldAirPressure);
        can_signal_get_float(&g_can_message_id022_ECU, &g_can_signal_id022_ECU_ThrottlePosition, &parameters->ThrottlePosition);
        can_signal_get_float(&g_can_message_id022_ECU, &g_can_signal_id022_ECU_RPM, &parameters->RPM);
        msgs_bitmap |= 1 << (can_msg->Id - 0x020);
        break;
      case 0x023:
        can_signal_get_float(&g_can_message_id023_ECU, &g_can_signal_id023_ECU_FuelRatio, &parameters->FuelRatio);
        can_signal_get_float(&g_can_message_id023_ECU, &g_can_signal_id023_ECU_FuelRatioDiff, &parameters->FuelRatioDiff);
        can_signal_get_float(&g_can_message_id023_ECU, &g_can_signal_id023_ECU_LambdaValue, &parameters->LambdaValue);
        can_signal_get_float(&g_can_message_id023_ECU, &g_can_signal_id023_ECU_LambdaTemperature, &parameters->LambdaTemperature);
        can_signal_get_float(&g_can_message_id023_ECU, &g_can_signal_id023_ECU_LambdaHeaterVoltage, &parameters->LambdaHeaterVoltage);
        can_signal_get_float(&g_can_message_id023_ECU, &g_can_signal_id023_ECU_ShortTermCorrection, &parameters->ShortTermCorrection);
        can_signal_get_float(&g_can_message_id023_ECU, &g_can_signal_id023_ECU_LongTermCorrection, &parameters->LongTermCorrection);
        can_signal_get_float(&g_can_message_id023_ECU, &g_can_signal_id023_ECU_IdleCorrection, &parameters->IdleCorrection);
        msgs_bitmap |= 1 << (can_msg->Id - 0x020);
        break;
      case 0x024:
        can_signal_get_float(&g_can_message_id024_ECU, &g_can_signal_id024_ECU_Speed, &parameters->Speed);
        can_signal_get_float(&g_can_message_id024_ECU, &g_can_signal_id024_ECU_MassAirFlow, &parameters->MassAirFlow);
        can_signal_get_float(&g_can_message_id024_ECU, &g_can_signal_id024_ECU_CyclicAirFlow, &parameters->CyclicAirFlow);
        can_signal_get_float(&g_can_message_id024_ECU, &g_can_signal_id024_ECU_EffectiveVolume, &parameters->EffectiveVolume);
        can_signal_get_float(&g_can_message_id024_ECU, &g_can_signal_id024_ECU_EngineLoad, &parameters->EngineLoad);
        can_signal_get_float(&g_can_message_id024_ECU, &g_can_signal_id024_ECU_EstimatedPower, &parameters->EstimatedPower);
        can_signal_get_float(&g_can_message_id024_ECU, &g_can_signal_id024_ECU_EstimatedTorque, &parameters->EstimatedTorque);
        msgs_bitmap |= 1 << (can_msg->Id - 0x020);
        break;
      case 0x025:
        can_signal_get_float(&g_can_message_id025_ECU, &g_can_signal_id025_ECU_WishFuelRatio, &parameters->WishFuelRatio);
        can_signal_get_float(&g_can_message_id025_ECU, &g_can_signal_id025_ECU_IdleValvePosition, &parameters->IdleValvePosition);
        can_signal_get_float(&g_can_message_id025_ECU, &g_can_signal_id025_ECU_IdleRegThrRPM, &parameters->IdleRegThrRPM);
        can_signal_get_float(&g_can_message_id025_ECU, &g_can_signal_id025_ECU_WishIdleRPM, &parameters->WishIdleRPM);
        can_signal_get_float(&g_can_message_id025_ECU, &g_can_signal_id025_ECU_WishIdleMassAirFlow, &parameters->WishIdleMassAirFlow);
        can_signal_get_float(&g_can_message_id025_ECU, &g_can_signal_id025_ECU_WishIdleValvePosition, &parameters->WishIdleValvePosition);
        can_signal_get_float(&g_can_message_id025_ECU, &g_can_signal_id025_ECU_WishIdleIgnitionAdvance, &parameters->WishIdleIgnitionAdvance);
        can_signal_get_float(&g_can_message_id025_ECU, &g_can_signal_id025_ECU_IdleSpeedShift, &parameters->IdleSpeedShift);
        msgs_bitmap |= 1 << (can_msg->Id - 0x020);
        break;
      case 0x026:
        can_signal_get_float(&g_can_message_id026_ECU, &g_can_signal_id026_ECU_InjectionPhase, &parameters->InjectionPhase);
        can_signal_get_float(&g_can_message_id026_ECU, &g_can_signal_id026_ECU_InjectionPhaseDuration, &parameters->InjectionPhaseDuration);
        can_signal_get_float(&g_can_message_id026_ECU, &g_can_signal_id026_ECU_InjectionPulse, &parameters->InjectionPulse);
        can_signal_get_float(&g_can_message_id026_ECU, &g_can_signal_id026_ECU_InjectionDutyCycle, &parameters->InjectionDutyCycle);
        can_signal_get_float(&g_can_message_id026_ECU, &g_can_signal_id026_ECU_IgnitionPulse, &parameters->IgnitionPulse);
        can_signal_get_float(&g_can_message_id026_ECU, &g_can_signal_id026_ECU_InjectionLag, &parameters->InjectionLag);
        can_signal_get_float(&g_can_message_id026_ECU, &g_can_signal_id026_ECU_TspsRelativePosition, &parameters->TspsRelativePosition);
        can_signal_get_float(&g_can_message_id026_ECU, &g_can_signal_id026_ECU_IgnitionAdvance, &parameters->IgnitionAdvance);
        msgs_bitmap |= 1 << (can_msg->Id - 0x020);
        break;
      case 0x027:
        can_signal_get_float(&g_can_message_id027_ECU, &g_can_signal_id027_ECU_EnrichmentSyncAmount, &parameters->EnrichmentSyncAmount);
        can_signal_get_float(&g_can_message_id027_ECU, &g_can_signal_id027_ECU_EnrichmentAsyncAmount, &parameters->EnrichmentAsyncAmount);
        can_signal_get_float(&g_can_message_id027_ECU, &g_can_signal_id027_ECU_EnrichmentStartLoad, &parameters->EnrichmentStartLoad);
        can_signal_get_float(&g_can_message_id027_ECU, &g_can_signal_id027_ECU_EnrichmentLoadDerivative, &parameters->EnrichmentLoadDerivative);
        can_signal_get_float(&g_can_message_id027_ECU, &g_can_signal_id027_ECU_InjectionEnrichment, &parameters->InjectionEnrichment);
        can_signal_get_float(&g_can_message_id027_ECU, &g_can_signal_id027_ECU_IdleWishToRpmRelation, &parameters->IdleWishToRpmRelation);
        msgs_bitmap |= 1 << (can_msg->Id - 0x020);
        break;
      case 0x028:
        can_signal_get_float(&g_can_message_id028_ECU, &g_can_signal_id028_ECU_DrivenKilometers, &parameters->DrivenKilometers);
        can_signal_get_float(&g_can_message_id028_ECU, &g_can_signal_id028_ECU_FuelConsumption, &parameters->FuelConsumption);
        can_signal_get_float(&g_can_message_id028_ECU, &g_can_signal_id028_ECU_FuelConsumed, &parameters->FuelConsumed);
        can_signal_get_float(&g_can_message_id028_ECU, &g_can_signal_id028_ECU_FuelHourly, &parameters->FuelHourly);
        msgs_bitmap |= 1 << (can_msg->Id - 0x020);
        break;
      case 0x029:
        can_signal_get_uint8(&g_can_message_id029_ECU, &g_can_signal_id029_ECU_LambdaValid, &parameters->LambdaValid);
        can_signal_get_uint8(&g_can_message_id029_ECU, &g_can_signal_id029_ECU_OilSensor, &parameters->OilSensor);
        can_signal_get_uint8(&g_can_message_id029_ECU, &g_can_signal_id029_ECU_FanForceSwitch, &parameters->FanForceSwitch);
        can_signal_get_uint8(&g_can_message_id029_ECU, &g_can_signal_id029_ECU_HandbrakeSensor, &parameters->HandbrakeSensor);
        can_signal_get_uint8(&g_can_message_id029_ECU, &g_can_signal_id029_ECU_ChargeSensor, &parameters->ChargeSensor);
        can_signal_get_uint8(&g_can_message_id029_ECU, &g_can_signal_id029_ECU_ClutchSensor, &parameters->ClutchSensor);
        can_signal_get_uint8(&g_can_message_id029_ECU, &g_can_signal_id029_ECU_IgnSensor, &parameters->IgnSensor);
        can_signal_get_uint8(&g_can_message_id029_ECU, &g_can_signal_id029_ECU_FuelPumpRelay, &parameters->FuelPumpRelay);
        can_signal_get_uint8(&g_can_message_id029_ECU, &g_can_signal_id029_ECU_FanRelay, &parameters->FanRelay);
        can_signal_get_uint8(&g_can_message_id029_ECU, &g_can_signal_id029_ECU_CheckEngine, &parameters->CheckEngine);
        can_signal_get_uint8(&g_can_message_id029_ECU, &g_can_signal_id029_ECU_StarterRelay, &parameters->StarterRelay);
        can_signal_get_uint8(&g_can_message_id029_ECU, &g_can_signal_id029_ECU_FanSwitch, &parameters->FanSwitch);
        can_signal_get_uint8(&g_can_message_id029_ECU, &g_can_signal_id029_ECU_IgnOutput, &parameters->IgnOutput);
        can_signal_get_uint8(&g_can_message_id029_ECU, &g_can_signal_id029_ECU_StartAllowed, &parameters->StartAllowed);
        can_signal_get_uint8(&g_can_message_id029_ECU, &g_can_signal_id029_ECU_IsRunning, &parameters->IsRunning);
        can_signal_get_uint8(&g_can_message_id029_ECU, &g_can_signal_id029_ECU_IsCheckEngine, &parameters->IsCheckEngine);
        can_signal_get_uint8(&g_can_message_id029_ECU, &g_can_signal_id029_ECU_CylinderIgnitionBitmask, &parameters->CylinderIgnitionBitmask);
        can_signal_get_uint8(&g_can_message_id029_ECU, &g_can_signal_id029_ECU_CylinderInjectionBitmask, &parameters->CylinderInjectionBitmask);
        can_signal_get_float(&g_can_message_id029_ECU, &g_can_signal_id029_ECU_PowerVoltage, &parameters->PowerVoltage);
        can_signal_get_uint8(&g_can_message_id029_ECU, &g_can_signal_id029_ECU_IdleFlag, &parameters->IdleFlag);
        can_signal_get_uint8(&g_can_message_id029_ECU, &g_can_signal_id029_ECU_IdleCorrFlag, &parameters->IdleCorrFlag);
        can_signal_get_uint8(&g_can_message_id029_ECU, &g_can_signal_id029_ECU_IdleEconFlag, &parameters->IdleEconFlag);
        can_signal_get_uint8(&g_can_message_id029_ECU, &g_can_signal_id029_ECU_SwitchPosition, &parameters->SwitchPosition);
        can_signal_get_uint8(&g_can_message_id029_ECU, &g_can_signal_id029_ECU_CurrentTable, &parameters->CurrentTable);
        can_signal_get_uint8(&g_can_message_id029_ECU, &g_can_signal_id029_ECU_InjectorChannel, &parameters->InjectorChannel);
        msgs_bitmap |= 1 << (can_msg->Id - 0x020);
        break;
      case 0x02A:
        can_signal_get_float(&g_can_message_id02A_ECU, &g_can_signal_id02A_ECU_EtcAdcTps1, &parameters->AdcEtcTps1);
        can_signal_get_float(&g_can_message_id02A_ECU, &g_can_signal_id02A_ECU_EtcAdcTps2, &parameters->AdcEtcTps2);
        can_signal_get_float(&g_can_message_id02A_ECU, &g_can_signal_id02A_ECU_EtcAdcPedal1, &parameters->AdcEtcPedal1);
        can_signal_get_float(&g_can_message_id02A_ECU, &g_can_signal_id02A_ECU_EtcAdcPedal2, &parameters->AdcEtcPedal2);
        can_signal_get_float(&g_can_message_id02A_ECU, &g_can_signal_id02A_ECU_EtcAdcRsvd5, &parameters->AdcEtcRsvd5);
        can_signal_get_float(&g_can_message_id02A_ECU, &g_can_signal_id02A_ECU_EtcAdcRsvd6, &parameters->AdcEtcRsvd6);
        can_signal_get_float(&g_can_message_id02A_ECU, &g_can_signal_id02A_ECU_EtcAdcReferenceVoltage, &parameters->AdcEtcReferenceVoltage);
        can_signal_get_float(&g_can_message_id02A_ECU, &g_can_signal_id02A_ECU_EtcAdcPowerVoltage, &parameters->AdcEtcPowerVoltage);
        msgs_bitmap |= 1 << (can_msg->Id - 0x020);
        break;
      case 0x02B:
        can_signal_get_float(&g_can_message_id02B_ECU, &g_can_signal_id02B_ECU_EtcThrottleTargetPosition, &parameters->ThrottleTargetPosition);
        can_signal_get_float(&g_can_message_id02B_ECU, &g_can_signal_id02B_ECU_EtcThrottleDefaultPosition, &parameters->ThrottleDefaultPosition);
        can_signal_get_float(&g_can_message_id02B_ECU, &g_can_signal_id02B_ECU_EtcWishThrottleTargetPosition, &parameters->WishThrottleTargetPosition);
        can_signal_get_float(&g_can_message_id02B_ECU, &g_can_signal_id02B_ECU_EtcPedalPosition, &parameters->PedalPosition);
        can_signal_get_uint8(&g_can_message_id02B_ECU, &g_can_signal_id02B_ECU_EtcStandaloneFlag, &parameters->EtcStandaloneFlag);
        can_signal_get_uint8(&g_can_message_id02B_ECU, &g_can_signal_id02B_ECU_EtcMotorActive, &parameters->EtcMotorActiveFlag);
        can_signal_get_uint8(&g_can_message_id02B_ECU, &g_can_signal_id02B_ECU_EtcMotorFullCloseFlag, &parameters->EtcMotorFullCloseFlag);
        can_signal_get_uint8(&g_can_message_id02B_ECU, &g_can_signal_id02B_ECU_EtcInCruizeStart, &parameters->EtcInCruizeStart);
        can_signal_get_uint8(&g_can_message_id02B_ECU, &g_can_signal_id02B_ECU_EtcInCruizeStop, &parameters->EtcInCruizeStop);
        can_signal_get_uint8(&g_can_message_id02B_ECU, &g_can_signal_id02B_ECU_EtcInBrake, &parameters->EtcInBrake);
        can_signal_get_uint8(&g_can_message_id02B_ECU, &g_can_signal_id02B_ECU_EtcInRsvd4, &parameters->EtcInRsvd4);
        can_signal_get_uint8(&g_can_message_id02B_ECU, &g_can_signal_id02B_ECU_EtcInRsvd5, &parameters->EtcInRsvd5);
        can_signal_get_uint8(&g_can_message_id02B_ECU, &g_can_signal_id02B_ECU_EtcInRsvd6, &parameters->EtcInRsvd6);
        can_signal_get_uint8(&g_can_message_id02B_ECU, &g_can_signal_id02B_ECU_EtcOutCruizeG, &parameters->EtcOutCruizeG);
        can_signal_get_uint8(&g_can_message_id02B_ECU, &g_can_signal_id02B_ECU_EtcOutCruizeR, &parameters->EtcOutCruizeR);
        can_signal_get_uint8(&g_can_message_id02B_ECU, &g_can_signal_id02B_ECU_EtcOutRsvd3, &parameters->EtcOutRsvd3);
        can_signal_get_uint8(&g_can_message_id02B_ECU, &g_can_signal_id02B_ECU_EtcOutRsvd4, &parameters->EtcOutRsvd4);
        msgs_bitmap |= 1 << (can_msg->Id - 0x020);
        break;
      default:
        break;
    }

    if(msgs_bitmap >= msgs_expected) {
      led_set(LedCan, LedShort);
      logger_parameters->timestamp = gTick64;
      for(int i = 0; i < ITEMSOF(gParamsFifo); i++) {
        if(gParamsFifo[i].buffer && gParamsFifo[i].info.capacity) {
          protPush(&gParamsFifo[i], logger_parameters);
        }
      }
      msgs_bitmap = 0;
    }
  }
  return status;
}

void StartUsbTask(void *argument)
{
  struct sLogDriver driver = {0};

  MX_USB_HOST_Init();

  driver.fifo = &gParamsFifo[0];
  driver.fatfs = &USBHFatFS;
  driver.file = &USBHFile;
  driver.path = USBHPath;
  driver.led = LedUsb;
  protInit(driver.fifo, gParamsBuffer[1], sizeof(sLoggerParameters), PARAMS_BUFFER_SIZE);

  driver_loop(&driver);
}

void StartSdioTask(void *argument)
{
  struct sLogDriver driver = {0};

  driver.fifo = &gParamsFifo[1];
  driver.fatfs = &SDFatFS;
  driver.file = &SDFile;
  driver.path = SDPath;
  driver.led = LedSdio;
  protInit(driver.fifo, gParamsBuffer[0], sizeof(sLoggerParameters), PARAMS_BUFFER_SIZE);

  driver_loop(&driver);
}

void StartCanTask(void *argument)
{
  uint64_t now, last;
  sLoggerParameters parameters = {0};
  static sCanRawMessage message = {0};
  int8_t status;

  can_init(&hcan1);

  const uint16_t filter_ids[] = { 0x020, 0x028 };
  const uint16_t filter_masks[] = { 0x7F8, 0x7F8 };
  can_start(filter_ids, filter_masks, ITEMSOF(filter_ids));

  led_set(LedCan, LedOn);
  led_set_post(LedCan, LedOn);

  can_message_register_msg(&g_can_message_id020_ECU);
  can_message_register_msg(&g_can_message_id021_ECU);
  can_message_register_msg(&g_can_message_id022_ECU);
  can_message_register_msg(&g_can_message_id023_ECU);
  can_message_register_msg(&g_can_message_id024_ECU);
  can_message_register_msg(&g_can_message_id025_ECU);
  can_message_register_msg(&g_can_message_id026_ECU);
  can_message_register_msg(&g_can_message_id027_ECU);
  can_message_register_msg(&g_can_message_id028_ECU);
  can_message_register_msg(&g_can_message_id029_ECU);
  can_message_register_msg(&g_can_message_id02A_ECU);
  can_message_register_msg(&g_can_message_id02B_ECU);

  now = gTick64;
  last = now;

  while(1)
  {
    now = gTick64;

    can_loop();

    status = can_receive(&message);
    if(status > 0) {
      ecu_can_process_message(&message, &parameters);
    }

    if(now - last > 1000) {
      can_signal_append_uint(&g_can_message_id110_LOG_ECU, &g_can_signal_id110_LOG_ECU_Unique, (uint16_t)now);
      can_message_send(&g_can_message_id110_LOG_ECU);
      last = now;
    }

    osDelay(1);
  }
}

void StartKlineTask(void *argument)
{
  led_set(LedKline, LedOff);
  for(;;)
  {
    osDelay(1000);
  }
}

void tasksInit(void)
{
  memset(gConfigBitmap, 0, sizeof(gConfigBitmap));
  for(int i = 0; i < ITEMSOF(gParameters); i++) {
    BIT_SET(gConfigBitmap, i);
  }

  h_task_time = osThreadNew(StartTimeTask, NULL, &attrs_task_time);
  //h_task_usb = osThreadNew(StartUsbTask, NULL, &attrs_task_usb);
  h_task_sdio = osThreadNew(StartSdioTask, NULL, &attrs_task_sdio);
  h_task_can = osThreadNew(StartCanTask, NULL, &attrs_task_can);
  h_task_kline = osThreadNew(StartKlineTask, NULL, &attrs_task_kline);
}
